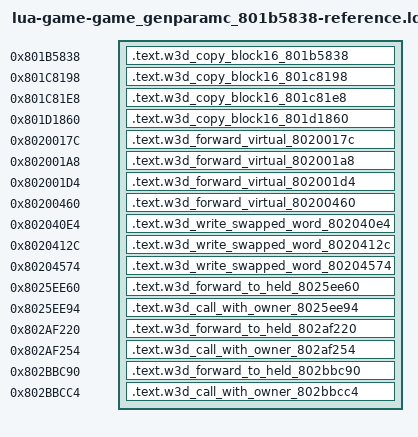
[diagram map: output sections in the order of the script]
/* Generated reference-only placements. All bodies are source-built. */
OUTPUT_FORMAT("elf32-powerpc")
OUTPUT_ARCH(powerpc)
ENTRY(w3d_copy_block16_801b5838)
_SDA_BASE_ = 0x804b2540;
_SDA2_BASE_ = 0x804c2540;
fn_802047e0 = 0x802047e0;
SECTIONS {
  .text.w3d_copy_block16_801b5838 0x801b5838 : { *(.text.w3d_copy_block16_801b5838) }
  .text.w3d_copy_block16_801c8198 0x801c8198 : { *(.text.w3d_copy_block16_801c8198) }
  .text.w3d_copy_block16_801c81e8 0x801c81e8 : { *(.text.w3d_copy_block16_801c81e8) }
  .text.w3d_copy_block16_801d1860 0x801d1860 : { *(.text.w3d_copy_block16_801d1860) }
  .text.w3d_forward_virtual_8020017c 0x8020017c : { *(.text.w3d_forward_virtual_8020017c) }
  .text.w3d_forward_virtual_802001a8 0x802001a8 : { *(.text.w3d_forward_virtual_802001a8) }
  .text.w3d_forward_virtual_802001d4 0x802001d4 : { *(.text.w3d_forward_virtual_802001d4) }
  .text.w3d_forward_virtual_80200460 0x80200460 : { *(.text.w3d_forward_virtual_80200460) }
  .text.w3d_write_swapped_word_802040e4 0x802040e4 : { *(.text.w3d_write_swapped_word_802040e4) }
  .text.w3d_write_swapped_word_8020412c 0x8020412c : { *(.text.w3d_write_swapped_word_8020412c) }
  .text.w3d_write_swapped_word_80204574 0x80204574 : { *(.text.w3d_write_swapped_word_80204574) }
  .text.w3d_forward_to_held_8025ee60 0x8025ee60 : { *(.text.w3d_forward_to_held_8025ee60) }
  .text.w3d_call_with_owner_8025ee94 0x8025ee94 : { *(.text.w3d_call_with_owner_8025ee94) }
  .text.w3d_forward_to_held_802af220 0x802af220 : { *(.text.w3d_forward_to_held_802af220) }
  .text.w3d_call_with_owner_802af254 0x802af254 : { *(.text.w3d_call_with_owner_802af254) }
  .text.w3d_forward_to_held_802bbc90 0x802bbc90 : { *(.text.w3d_forward_to_held_802bbc90) }
  .text.w3d_call_with_owner_802bbcc4 0x802bbcc4 : { *(.text.w3d_call_with_owner_802bbcc4) }
  /DISCARD/ : { *(.text*) *(.rodata*) *(.data*) *(.bss*) *(.sdata*) *(.sbss*) *(.comment) }
}
